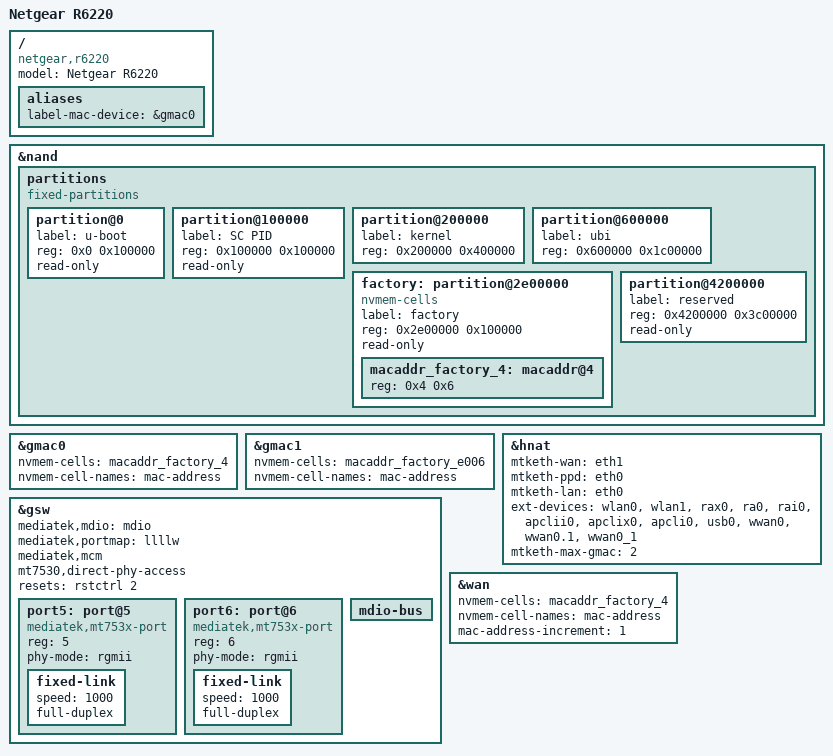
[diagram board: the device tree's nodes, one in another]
// SPDX-License-Identifier: GPL-2.0-only

#include "mt7621_netgear_sercomm_ayx.dtsi"

/ {
	compatible = "netgear,r6220", "mediatek,mt7621-soc";
	model = "Netgear R6220";

	aliases {
		label-mac-device = &gmac0;
	};
};

&nand {
	status = "okay";

	partitions {
		compatible = "fixed-partitions";
		#address-cells = <1>;
		#size-cells = <1>;

		partition@0 {
			label = "u-boot";
			reg = <0x0 0x100000>;
			read-only;
		};

		partition@100000 {
			label = "SC PID";
			reg = <0x100000 0x100000>;
			read-only;
		};

		partition@200000 {
			label = "kernel";
			reg = <0x200000 0x400000>;
		};

		partition@600000 {
			label = "ubi";
			reg = <0x600000 0x1c00000>;
		};

		factory: partition@2e00000 {
			label = "factory";
			reg = <0x2e00000 0x100000>;
			read-only;
		};

		partition@4200000 {
			label = "reserved";
			reg = <0x4200000 0x3c00000>;
			read-only;
		};
	};
};

&gmac0 {
	nvmem-cells = <&macaddr_factory_4>;
	nvmem-cell-names = "mac-address";
};

&gmac1 {
	nvmem-cells = <&macaddr_factory_e006>;
	nvmem-cell-names = "mac-address";
};

&hnat {
        mtketh-wan = "eth1";
        mtketh-ppd = "eth0";
        mtketh-lan = "eth0";
	ext-devices = "wlan0","wlan1","rax0","ra0", "rai0","apclii0","apclix0", "apcli0","usb0","wwan0","wwan0.1","wwan0_1";
        mtketh-max-gmac = <2>;
        status = "okay";
};

&gsw {
	mediatek,mdio = <&mdio>;
	mediatek,portmap = "llllw";
	mediatek,mcm;
	mt7530,direct-phy-access;

	resets = <&rstctrl 2>;
	reset-names = "mcm";

	port5: port@5 {
		compatible = "mediatek,mt753x-port";
		reg = <5>;
		phy-mode = "rgmii";
		fixed-link {
			speed = <1000>;
			full-duplex;
		};
	};

	port6: port@6 {
		compatible = "mediatek,mt753x-port";
		reg = <6>;
		phy-mode = "rgmii";
		fixed-link {
			speed = <1000>;
			full-duplex;
		};
	};

	mdio-bus {
		#address-cells = <1>;
		#size-cells = <0>;
	};
};


&wan {
	nvmem-cells = <&macaddr_factory_4>;
	nvmem-cell-names = "mac-address";
	mac-address-increment = <1>;
};

&factory {
	compatible = "nvmem-cells";
	#address-cells = <1>;
	#size-cells = <1>;

	macaddr_factory_4: macaddr@4 {
		reg = <0x4 0x6>;
	};
};
